# LargeDummyDevice register map
File version: 1.0
Registers are 32-bit, read-write, no defined reset value unless marked. A register's access mark holds for its fields unless they carry their own. Offsets are from the block's base; [hi:lo] are bit positions.

## PERIPHERAL_12
Base 0x4000B000
0x04 REG_1 — Register 1
  [32:28] FIELD_1, [29:26] FIELD_7, [30:26] FIELD_10, [29:25] FIELD_3, [25] FIELD_11, [24] FIELD_4, [25:23] FIELD_15, [24:22] FIELD_18, [25:21] FIELD_13, [22:18] FIELD_2, [21:18] FIELD_8, [14:11] FIELD_12, [9] FIELD_6, [11:7] FIELD_17, [5:3] FIELD_5, [3] FIELD_9, [5:3] FIELD_14, [6:2] FIELD_16
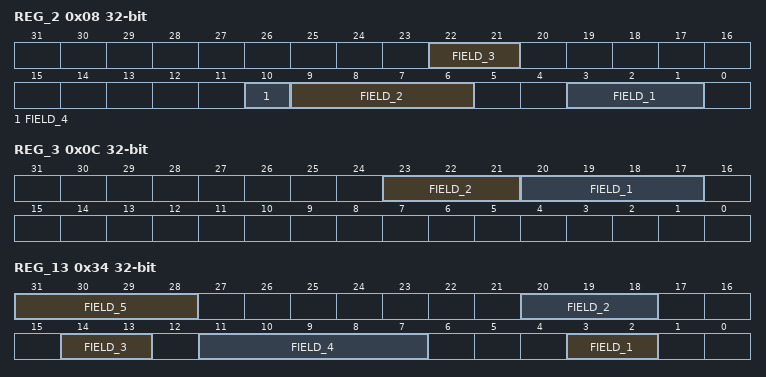
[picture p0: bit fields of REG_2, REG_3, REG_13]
0x08 REG_2 — Register 2
  [22:21] FIELD_3, [10] FIELD_4, [9:6] FIELD_2, [3:1] FIELD_1
0x0C REG_3 — Register 3
  [23:21] FIELD_2, [20:17] FIELD_1
0x10 REG_4 — Register 4
  [34:30] FIELD_1, [29:28] FIELD_12, [31:27] FIELD_9, [21] FIELD_6, [18:15] FIELD_10, [14:11] FIELD_2, [6:4] FIELD_5, [7:4] FIELD_8, [6:3] FIELD_3, [5:3] FIELD_4, [0] FIELD_7, [4:0] FIELD_11
0x14 REG_5 — Register 5
  [29] FIELD_5, [30:26] FIELD_6, [27:23] FIELD_11, [21] FIELD_1, [24:21] FIELD_3, [22:19] FIELD_13, [21:17] FIELD_8, [18:14] FIELD_10, [12:10] FIELD_7, [13:9] FIELD_12, [9:7] FIELD_14, [8:6] FIELD_9, [6:5] FIELD_2, [7:5] FIELD_4
0x18 REG_6 — Register 6
  [33:31] FIELD_21, [30] FIELD_9, [29:27] FIELD_7, [24:22] FIELD_2, [24:22] FIELD_4, [22] FIELD_11, [25:21] FIELD_13, [23:19] FIELD_16, [20:18] FIELD_10, [19:16] FIELD_20, [15:14] FIELD_3, [15:14] FIELD_23, [16:12] FIELD_5, [12:10] FIELD_19, [10:9] FIELD_14, [8] FIELD_8, [6] FIELD_6, [8:5] FIELD_17, [4] FIELD_1, [6:4] FIELD_15, [4:3] FIELD_12, [6:2] FIELD_22, [1] FIELD_18
0x1C REG_7 — Register 7
  [30:28] FIELD_1, [25] FIELD_5, [24:21] FIELD_3, [20:19] FIELD_7, [17:13] FIELD_6, [13:12] FIELD_4, [10:9] FIELD_2
0x20 REG_8 — Register 8
  [30:29] FIELD_8, [32:29] FIELD_23, [31:27] FIELD_15, [30:27] FIELD_25, [29:25] FIELD_11, [23] FIELD_4, [25:22] FIELD_22, [24:21] FIELD_14, [21] FIELD_17, [22:21] FIELD_19, [22:20] FIELD_1, [22:20] FIELD_18, [24:20] FIELD_26, [19:18] FIELD_27, [17:16] FIELD_13, [19:16] FIELD_21, [17:14] FIELD_20, [14:13] FIELD_2, [13] FIELD_5, [14:13] FIELD_7, [16:13] FIELD_12, [14:11] FIELD_6, [11:8] FIELD_10, [8:7] FIELD_24, [10:6] FIELD_9, [6:5] FIELD_16, [4:3] FIELD_28, [2:1] FIELD_3
0x24 REG_9 — Register 9
  [12:8] FIELD_4, [7:6] FIELD_3, [5:4] FIELD_1, [4:3] FIELD_2
0x28 REG_10 — Register 10
  [33:31] FIELD_5, [34:31] FIELD_6, [33:30] FIELD_14, [32:29] FIELD_10, [28] FIELD_4, [26:24] FIELD_13, [19:17] FIELD_2, [20:17] FIELD_11, [11:10] FIELD_7, [9] FIELD_9, [12:8] FIELD_8, [8] FIELD_12, [11:7] FIELD_1, [10:6] FIELD_3
0x2C REG_11 — Register 11
  [7] FIELD_1
0x30 REG_12 — Register 12
  [27:25] FIELD_1, [26:23] FIELD_3, [16] FIELD_5, [6:5] FIELD_2, [2] FIELD_4
0x34 REG_13 — Register 13
  [31:28] FIELD_5, [20:18] FIELD_2, [14:13] FIELD_3, [11:7] FIELD_4, [3:2] FIELD_1
0x38 REG_14 — Register 14
  [33:31] FIELD_21, [29:25] FIELD_8, [26:25] FIELD_17, [24:23] FIELD_4, [22] FIELD_2, [24:21] FIELD_11, [22:20] FIELD_3, [20:18] FIELD_14, [20:18] FIELD_18, [21:17] FIELD_15, [14] FIELD_20, [14:13] FIELD_10, [13] FIELD_16, [16:13] FIELD_19, [10:9] FIELD_6, [11:9] FIELD_9, [11:9] FIELD_23, [9:8] FIELD_5, [10:7] FIELD_7, [7:5] FIELD_1, [4:3] FIELD_13, [6:2] FIELD_12, [2:1] FIELD_22
0x3C REG_15 — Register 15
  [22] FIELD_3, [21:18] FIELD_5, [18:16] FIELD_1, [15:11] FIELD_4, [5:1] FIELD_2
0x40 REG_16 — Register 16
  [34:30] FIELD_7, [30:27] FIELD_6, [27:25] FIELD_12, [25:24] FIELD_5, [26:24] FIELD_10, [26:24] FIELD_14, [24:23] FIELD_21, [23:22] FIELD_8, [22:20] FIELD_17, [23:20] FIELD_22, [19] FIELD_11, [23:19] FIELD_23, [22:18] FIELD_16, [18:15] FIELD_24, [15:14] FIELD_18, [11] FIELD_4, [13:11] FIELD_20, [11:9] FIELD_13, [9:7] FIELD_19, [6] FIELD_1, [8:5] FIELD_25, [4:3] FIELD_15, [4:2] FIELD_3, [3:2] FIELD_9, [0] FIELD_2
0x44 REG_17 — Register 17
  [15:13] FIELD_1
0x48 REG_18 — Register 18
  [31] FIELD_5, [31:28] FIELD_13, [26:22] FIELD_1, [26:22] FIELD_9, [25:21] FIELD_22, [23:20] FIELD_20, [18] FIELD_2, [20:18] FIELD_10, [16] FIELD_17, [16:15] FIELD_4, [15] FIELD_18, [14] FIELD_12, [13] FIELD_16, [10] FIELD_7, [13:10] FIELD_21, [9:8] FIELD_6, [9:8] FIELD_11, [8] FIELD_15, [10:6] FIELD_14, [10:6] FIELD_23, [5:4] FIELD_3, [4] FIELD_8, [0] FIELD_19
0x4C REG_19 — Register 19
  [32:31] FIELD_21, [34:31] FIELD_27, [27] FIELD_2, [28:24] FIELD_13, [25:24] FIELD_24, [23] FIELD_7, [25:23] FIELD_14, [25:22] FIELD_29, [18:17] FIELD_9, [17] FIELD_17, [17] FIELD_19, [21:17] FIELD_23, [20:17] FIELD_26, [18:16] FIELD_8, [18:15] FIELD_16, [19:15] FIELD_28, [16:14] FIELD_25, [14:13] FIELD_10, [12] FIELD_3, [12] FIELD_15, [13:10] FIELD_18, [11:8] FIELD_4, [10:7] FIELD_20, [7:5] FIELD_11, [5:4] FIELD_6, [5:4] FIELD_12, [4:3] FIELD_22, [4:2] FIELD_5, [3:0] FIELD_1
